// *************************************************************************** *
// *                                                                           *
// *             Mini dbc file for diagnostic queries.                         *
// *             https://en.wikipedia.org/wiki/OBD-II_PIDs                     *
// *                                                                           *
// *************************************************************************** *

// *    ref https://en.wikipedia.org/wiki/OBD-II_PIDs                                                               *
// *    The diagnostic reader initiates a query using CAN ID 7DFh/2015 [clarification needed],                      *
// *    which acts as a broadcast address, and accepts responses from any ID in the range 7E8h/2024 to 7EFh/2031.   *
// *    ECUs that can respond to OBD queries listen both to the functional broadcast ID of 7DFh/2015 and one        *
// *    assigned ID in the range 7E0h/2015 to 7E7h/2023. Their response has an ID of their assigned ID plus 8 e.g.  *
// *    7E8h/2024 through 7EFh/2031.                                                                                *

VERSION "Relays"

BO_ 5 Relays_resp_set: 8 relay_client

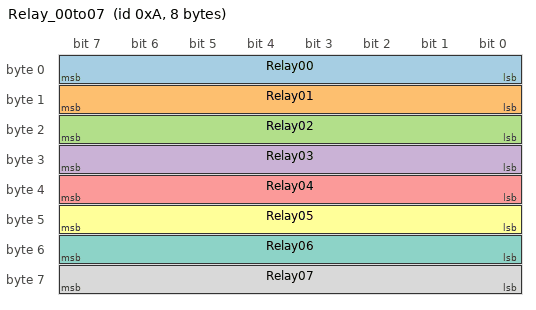
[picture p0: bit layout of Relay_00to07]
BO_ 10 Relay_00to07: 8 host_runner
 SG_ Relay00 : 7|8@0+ (1.0, 0.0) [0.0|255.0] "NoUnit" relay_client
 SG_ Relay01 : 15|8@0+ (1.0, 0.0) [0.0|255.0] "NoUnit" relay_client
 SG_ Relay02 : 23|8@0+ (1.0, 0.0) [0.0|255.0] "NoUnit" relay_client
 SG_ Relay03 : 31|8@0+ (1.0, 0.0) [0.0|255.0] "NoUnit" relay_client
 SG_ Relay04 : 39|8@0+ (1.0, 0.0) [0.0|255.0] "NoUnit" relay_client
 SG_ Relay05 : 47|8@0+ (1.0, 0.0) [0.0|255.0] "NoUnit" relay_client
 SG_ Relay06 : 55|8@0+ (1.0, 0.0) [0.0|255.0] "NoUnit" relay_client
 SG_ Relay07 : 63|8@0+ (1.0, 0.0) [0.0|255.0] "NoUnit" relay_client
